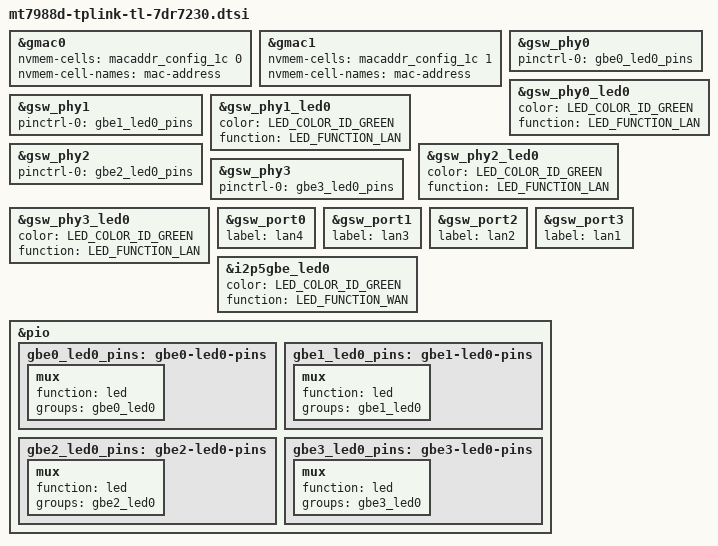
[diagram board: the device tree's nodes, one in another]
// SPDX-License-Identifier: GPL-2.0-or-later OR MIT

#include "mt7988d-tplink-tl-7dr72xx.dtsi"

&gmac0 {
	nvmem-cells = <&macaddr_config_1c 0>;
	nvmem-cell-names = "mac-address";
	status = "okay";
};

&gmac1 {
	nvmem-cells = <&macaddr_config_1c 1>;
	nvmem-cell-names = "mac-address";
};

&gsw_phy0 {
	pinctrl-names = "gbe-led";
	pinctrl-0 = <&gbe0_led0_pins>;
};

&gsw_phy0_led0 {
	color = <LED_COLOR_ID_GREEN>;
	function = LED_FUNCTION_LAN;
	status = "okay";
};

&gsw_phy1 {
	pinctrl-names = "gbe-led";
	pinctrl-0 = <&gbe1_led0_pins>;
};

&gsw_phy1_led0 {
	color = <LED_COLOR_ID_GREEN>;
	function = LED_FUNCTION_LAN;
	status = "okay";
};

&gsw_phy2 {
	pinctrl-names = "gbe-led";
	pinctrl-0 = <&gbe2_led0_pins>;
};

&gsw_phy2_led0 {
	color = <LED_COLOR_ID_GREEN>;
	function = LED_FUNCTION_LAN;
	status = "okay";
};

&gsw_phy3 {
	pinctrl-names = "gbe-led";
	pinctrl-0 = <&gbe3_led0_pins>;
};

&gsw_phy3_led0 {
	color = <LED_COLOR_ID_GREEN>;
	function = LED_FUNCTION_LAN;
	status = "okay";
};

&gsw_port0 {
	label = "lan4";
};

&gsw_port1 {
	label = "lan3";
};

&gsw_port2 {
	label = "lan2";
};

&gsw_port3 {
	label = "lan1";
};

&i2p5gbe_led0 {
	color = <LED_COLOR_ID_GREEN>;
	function = LED_FUNCTION_WAN;
};

&pio {
	gbe0_led0_pins: gbe0-led0-pins {
		mux {
			function = "led";
			groups = "gbe0_led0";
		};
	};

	gbe1_led0_pins: gbe1-led0-pins {
		mux {
			function = "led";
			groups = "gbe1_led0";
		};
	};

	gbe2_led0_pins: gbe2-led0-pins {
		mux {
			function = "led";
			groups = "gbe2_led0";
		};
	};

	gbe3_led0_pins: gbe3-led0-pins {
		mux {
			function = "led";
			groups = "gbe3_led0";
		};
	};
};
